# ISD9300_v3 register map
File version: 1.0
Registers are 32-bit, read-write, reset 0x0 unless marked. A register's access mark holds for its fields unless they carry their own. Offsets are from the block's base; [hi:lo] are bit positions; {n}, {i} and the like mark numbered series; 'fields as' and 'values as' point back to an identical list.

## I2C — I2C Register Map
Base 0x40020000
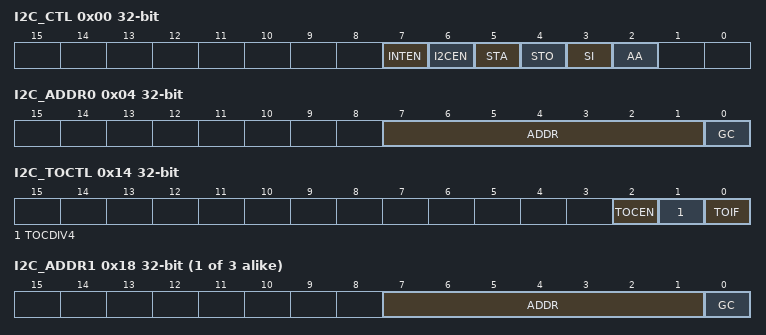
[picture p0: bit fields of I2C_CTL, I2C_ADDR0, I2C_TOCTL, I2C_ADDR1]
0x00 I2C_CTL — I2C Control Register
  [7] INTEN — Enable Interrupt
    0=Disable interrupt; 1=Enable interrupt CPU
  [6] I2CEN — I2C Controller Enable Bit. Set to enable I2C serial function block.
    0=Disable; 1=Enable
  [5] STA — I2C START Control Bit. Setting STA to logic 1 will enter master mode, the I2C hardware sends a START or repeat START condition to bus when the bus is free.
  [4] STO — I2C STOP Control Bit. In master mode, set STO to transmit a STOP condition to bus. I2C hardware will check the bus condition, when a STOP condition is detected this bit will be cleared by hardware automatically. In slave mode, setting STO resets I2C hardware to the defined "not addressed" slave mode. This means it is NO LONGER in the slave receiver mode able receive data from the master transmit device.
  [3] SI — I2C Interrupt Flag. When a new SIO state is present in the I2C_STATUS register, the SI flag is set by hardware, and if bit EI (I2C_CTL[7]) is set, the I2C interrupt is requested. SI must be cleared by software. Clear SI is by writing one to this bit.
  [2] AA — Assert Acknowledge Control Bit. 1. A slave is acknowledging the address sent from master, 2. The receiver devices are acknowledging the data sent by transmitter. When AA aaa 0 prior to address or data received, a Not acknowledged (high level to SDA) will be returned during the acknowledge clock pulse on the SCL line.
0x04 I2C_ADDR0 — I2C Slave address Register0
  [7:1] ADDR — I2C Address Register. The content of this register is irrelevant when I2C is in master mode. In the slave mode, the seven most significant bits must be loaded with the MCU's own address. The I2C hardware will react if any of the addresses are matched.
  [0] GC — General Call Function
    0=Disable General Call Function; 1=Enable General Call Function
0x08 I2C_DAT — I2C DATA Register
  [7:0] DAT — I2C Data Register. During master or slave transmit mode, data to be transmitted is written to this register. During master or slave receive mode, data that has been received may be read from this register.
0x0C I2C_STATUS ro
  [7:0] STATUS — I2C Status Register. The status register of I2C: The three least significant bits are always 0. The five most significant bits contain the status code. There are 26 possible status codes. When I2C_STATUS contains F8H, no serial interrupt is requested. All other I2C_STATUS values correspond to defined I2C states. When each of these states is entered, a status interrupt is requested (SI aaa 1). A valid status code is present in I2C_STATUS one PCLK cycle after SI is set by hardware and is still present one PCLK cycle after SI has been reset by software. In addition, states 00H stands for a Bus Error. A Bus Error occurs when a START or STOP condition is present at an illegal position in the frame. Example of illegal position are during the serial transfer of an address byte, a data byte or an acknowledge bit.
0x10 I2C_CLKDIV — I2C clock divided Register
  [7:0] DIVIDER — I2C Clock Divided Register. The I2C clock rate bits: Data Baud Rate of I2C aaa PCLK /(4x(I2C_CLKDIV+1)).
0x14 I2C_TOCTL — I2C Time out control Register
  [2] TOCEN — Time-Out Counter Control Bit. When enabled, the 14 bit time-out counter will start counting when SI is clear. Setting flag SI to high will reset counter and re-start up counting after SI is cleared.
    0=Disable; 1=Enable
  [1] TOCDIV4 — Time-Out Counter Input Clock Divide By 4. When enabled, the time-out clock is PCLK/4.
    0=Disable; 1=Enable
  [0] TOIF — Time-Out Flag
    0=No time-out; 1=Time-out flag is set by H/W. It can interrupt CPU. Write 1 to clear.
{0x14+4i} I2C_ADDR{i} (i=1..3) — I2C Slave address Register0
  fields as I2C_ADDR0
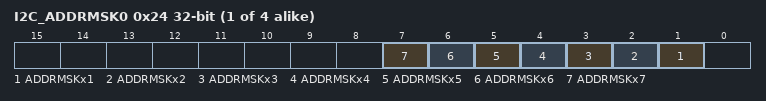
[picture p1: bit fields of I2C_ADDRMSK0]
{0x24+4i} I2C_ADDRMSK{i} (i=0..3) — I2C Slave address Mask Register0
  [all] fields
    0=Mask disable; 1=Mask enable (the received corresponding address bit is don't care.)
  [n] ADDRMSKx{n} (n=1..7) — I2C Address Mask Register. I2C bus controllers support multiple-address recognition with four address mask registers. Bits in this field mask the ADDRx registers masking bits from the address comparison.
